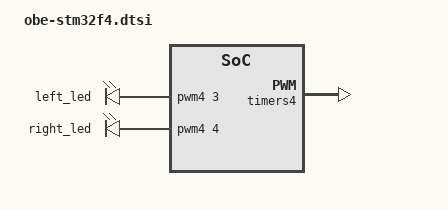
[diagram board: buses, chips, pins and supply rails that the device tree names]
/*
 * Copyright (c) 2023 The ZMK Contributors
 *
 * SPDX-License-Identifier: MIT
 */

&spi1 {
    status = "disabled";
};

&i2c1 {
    status = "disabled";
    pinctrl-0 = <&i2c1_scl_pb6 &i2c1_sda_pb7>;
    clock-frequency = <I2C_BITRATE_FAST>;
};

&timers4 {
    status = "okay";

    pwm4: pwm {
        status = "okay";
        pinctrl-0 = <&tim4_ch3_pb8 &tim4_ch4_pb9>;
        pinctrl-names = "default";
    };
};

/ {
    // Delete the existing GPIO LEDs.
    /delete-node/ indicator_leds;

    indicator_leds: indicator_leds {
        compatible = "pwm-leds";
        // Note: You cannot use PWM_MSEC here. It will fail silently.
        left_led: pwm_led_1 {
            pwms = <&pwm4 3 PWM_USEC(100) PWM_POLARITY_NORMAL>;
        };
        right_led: pwm_led_2 {
            pwms = <&pwm4 4 PWM_USEC(100) PWM_POLARITY_NORMAL>;
        };
    };
};
